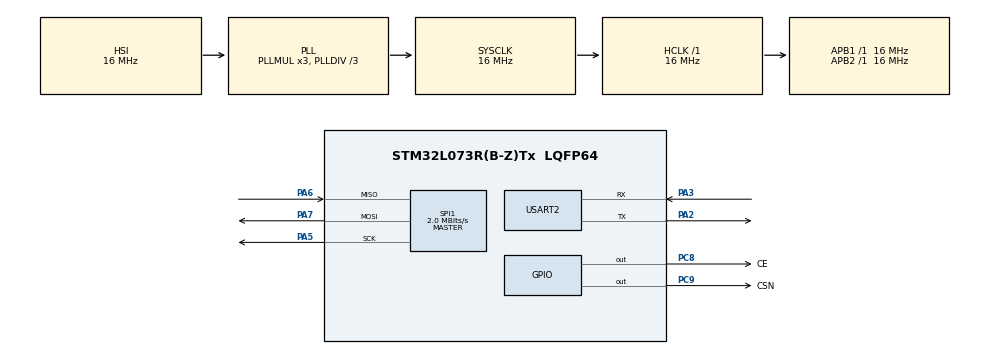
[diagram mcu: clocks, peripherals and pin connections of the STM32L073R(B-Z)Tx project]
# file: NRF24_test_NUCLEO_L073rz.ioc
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Mcu.Family=STM32L0
Mcu.Name=STM32L073R(B-Z)Tx
Mcu.Package=LQFP64
NVIC.USART2_IRQn=true\:0\:0\:false\:false\:true\:true\:true
PA2.Mode=Asynchronous
PA2.Signal=USART2_TX
PA3.Mode=Asynchronous
PA3.Signal=USART2_RX
PA5.Mode=Full_Duplex_Master
PA5.Signal=SPI1_SCK
PA6.Mode=Full_Duplex_Master
PA6.Signal=SPI1_MISO
PA7.Mode=Full_Duplex_Master
PA7.Signal=SPI1_MOSI
PC8.GPIO_Label=CE
PC8.GPIO_PuPd=GPIO_PULLUP
PC8.Signal=GPIO_Output
PC9.GPIO_Label=CSN
PC9.GPIO_PuPd=GPIO_PULLUP
PC9.Signal=GPIO_Output
ProjectManager.HeapSize=0x200
ProjectManager.StackSize=0x400
ProjectManager.TargetToolchain=TrueSTUDIO
RCC.AHBFreq_Value=16000000
RCC.APB1Freq_Value=16000000
RCC.APB1TimFreq_Value=16000000
RCC.APB2Freq_Value=16000000
RCC.APB2TimFreq_Value=16000000
RCC.HCLKFreq_Value=16000000
RCC.HSE_VALUE=8000000
RCC.HSI16_VALUE=16000000
RCC.HSI48_VALUE=48000000
RCC.HSI_VALUE=16000000
RCC.LSE_VALUE=32768
RCC.MSI_VALUE=2097000
RCC.PLLDIV=RCC_PLLDIV_3
RCC.SYSCLKFreq_VALUE=16000000
RCC.SYSCLKSource=RCC_SYSCLKSOURCE_PLLCLK
RCC.VCOOutputFreq_Value=48000000
SPI1.BaudRatePrescaler=SPI_BAUDRATEPRESCALER_8
SPI1.CalculateBaudRate=2.0 MBits/s
SPI1.DataSize=SPI_DATASIZE_8BIT
SPI1.Direction=SPI_DIRECTION_2LINES
SPI1.Mode=SPI_MODE_MASTER
SPI1.VirtualType=VM_MASTER
USART2.VirtualMode-Asynchronous=VM_ASYNC
board=custom

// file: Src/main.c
/* USER CODE BEGIN Header */
/**
  ******************************************************************************
  * @file           : main.c
  * @brief          : Main program body
  ******************************************************************************
  * @attention
  *
  * <h2><center>&copy; Copyright (c) 2019 STMicroelectronics.
  * All rights reserved.</center></h2>
  *
  * This software component is licensed by ST under BSD 3-Clause license,
  * the "License"; You may not use this file except in compliance with the
  * License. You may obtain a copy of the License at:
  *                        opensource.org/licenses/BSD-3-Clause
  *
  ******************************************************************************
  */
/* USER CODE END Header */

#include "main.h"
#include "spi.h"
#include "usart.h"
#include "gpio.h"

/* USER CODE BEGIN Includes */
#include "MY_NRF24.h"
/* USER CODE END Includes */

void SystemClock_Config(void);

/* USER CODE BEGIN 0 */
uint64_t RxpipeAddrs = 0x11223344AA;
char myRxData[50];
char myAckPayload[32] = "Ack by STML0!";
/* USER CODE END 0 */

int main(void)
{

  /* MCU Configuration--------------------------------------------------------*/

  /* Reset of all peripherals, Initializes the Flash interface and the Systick. */
  HAL_Init();

  /* Configure the system clock */
  SystemClock_Config();

  /* Initialize all configured peripherals */
  MX_GPIO_Init();
  MX_SPI1_Init();
  MX_USART2_UART_Init();
  /* USER CODE BEGIN 2 */
	NRF24_begin(CSN_GPIO_Port, CSN_Pin, CE_Pin, hspi1);
	nrf24_DebugUART_Init(huart2);

	NRF24_openReadingPipe(0, RxpipeAddrs);
//	NRF24_setAutoAck(false);
//	NRF24_setChannel(52);
//	NRF24_setPayloadSize(32);
//	NRF24_enableDynamicPayloads();
//	NRF24_enableAckPayload();
	printRadioSettings();

	NRF24_startListening();
  /* USER CODE END 2 */

  /* Infinite loop */
  while (1)
  {

    /* USER CODE BEGIN 3 */
		if(NRF24_available())
		{
			NRF24_read(myRxData, 32);
			NRF24_writeAckPayload(1, myAckPayload, 32);
			myRxData[32] = '\r'; myRxData[32+1] = '\n';
			HAL_UART_Transmit(&huart2, (uint8_t *)myRxData, 32+2, 10);
		}
  }
  /* USER CODE END 3 */
}

void SystemClock_Config(void)
{
  RCC_OscInitTypeDef RCC_OscInitStruct = {0};
  RCC_ClkInitTypeDef RCC_ClkInitStruct = {0};
  RCC_PeriphCLKInitTypeDef PeriphClkInit = {0};

  /** Configure the main internal regulator output voltage
  */
  __HAL_PWR_VOLTAGESCALING_CONFIG(PWR_REGULATOR_VOLTAGE_SCALE1);
  /** Initializes the CPU, AHB and APB busses clocks
  */
  RCC_OscInitStruct.OscillatorType = RCC_OSCILLATORTYPE_HSI;
  RCC_OscInitStruct.HSIState = RCC_HSI_ON;
  RCC_OscInitStruct.HSICalibrationValue = RCC_HSICALIBRATION_DEFAULT;
  RCC_OscInitStruct.PLL.PLLState = RCC_PLL_ON;
  RCC_OscInitStruct.PLL.PLLSource = RCC_PLLSOURCE_HSI;
  RCC_OscInitStruct.PLL.PLLMUL = RCC_PLLMUL_3;
  RCC_OscInitStruct.PLL.PLLDIV = RCC_PLLDIV_3;
  if (HAL_RCC_OscConfig(&RCC_OscInitStruct) != HAL_OK)
  {
    Error_Handler();
  }
  /** Initializes the CPU, AHB and APB busses clocks
  */
  RCC_ClkInitStruct.ClockType = RCC_CLOCKTYPE_HCLK|RCC_CLOCKTYPE_SYSCLK
                              |RCC_CLOCKTYPE_PCLK1|RCC_CLOCKTYPE_PCLK2;
  RCC_ClkInitStruct.SYSCLKSource = RCC_SYSCLKSOURCE_PLLCLK;
  RCC_ClkInitStruct.AHBCLKDivider = RCC_SYSCLK_DIV1;
  RCC_ClkInitStruct.APB1CLKDivider = RCC_HCLK_DIV1;
  RCC_ClkInitStruct.APB2CLKDivider = RCC_HCLK_DIV1;

  if (HAL_RCC_ClockConfig(&RCC_ClkInitStruct, FLASH_LATENCY_0) != HAL_OK)
  {
    Error_Handler();
  }
  PeriphClkInit.PeriphClockSelection = RCC_PERIPHCLK_USART2;
  PeriphClkInit.Usart2ClockSelection = RCC_USART2CLKSOURCE_PCLK1;
  if (HAL_RCCEx_PeriphCLKConfig(&PeriphClkInit) != HAL_OK)
  {
    Error_Handler();
  }
}

void Error_Handler(void)
{
}

/************************ (C) COPYRIGHT STMicroelectronics *****END OF FILE****/
